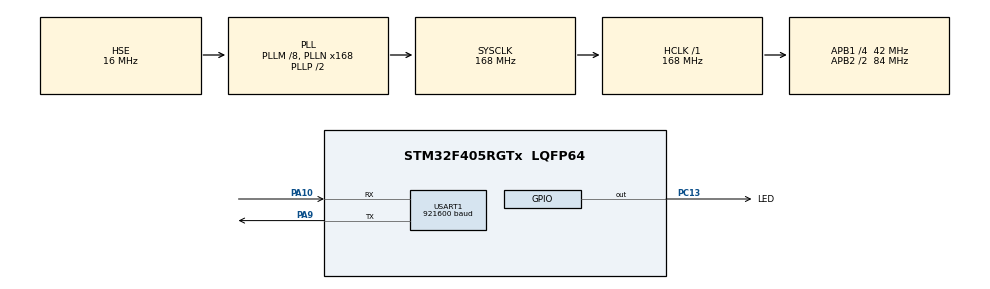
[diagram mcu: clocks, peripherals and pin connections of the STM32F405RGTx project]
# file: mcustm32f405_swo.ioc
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Mcu.Family=STM32F4
Mcu.Name=STM32F405RGTx
Mcu.Package=LQFP64
NVIC.PriorityGroup=NVIC_PRIORITYGROUP_4
NVIC.TIM2_IRQn=true\:0\:0\:false\:false\:true\:true\:true\:true
NVIC.TIM5_IRQn=true\:0\:0\:false\:false\:true\:true\:true\:true
PA10.Mode=Asynchronous
PA10.Signal=USART1_RX
PA13.Mode=Trace_Asynchronous_SW
PA13.Signal=SYS_JTMS-SWDIO
PA14.Mode=Trace_Asynchronous_SW
PA14.Signal=SYS_JTCK-SWCLK
PA9.Mode=Asynchronous
PA9.Signal=USART1_TX
PB3.Mode=Trace_Asynchronous_SW
PB3.Signal=SYS_JTDO-SWO
PC13-ANTI_TAMP.GPIO_Label=LED
PC13-ANTI_TAMP.GPIO_ModeDefaultOutputPP=GPIO_MODE_OUTPUT_OD
PC13-ANTI_TAMP.GPIO_PuPd=GPIO_NOPULL
PC13-ANTI_TAMP.PinState=GPIO_PIN_SET
PC13-ANTI_TAMP.Signal=GPIO_Output
PH0-OSC_IN.Mode=HSE-External-Oscillator
PH0-OSC_IN.Signal=RCC_OSC_IN
PH1-OSC_OUT.Mode=HSE-External-Oscillator
PH1-OSC_OUT.Signal=RCC_OSC_OUT
ProjectManager.HeapSize=0x200
ProjectManager.StackSize=0x400
ProjectManager.TargetToolchain=STM32CubeIDE
RCC.48MHZClocksFreq_Value=84000000
RCC.AHBFreq_Value=168000000
RCC.APB1CLKDivider=RCC_HCLK_DIV4
RCC.APB1Freq_Value=42000000
RCC.APB1TimFreq_Value=84000000
RCC.APB2CLKDivider=RCC_HCLK_DIV2
RCC.APB2Freq_Value=84000000
RCC.APB2TimFreq_Value=168000000
RCC.CortexFreq_Value=168000000
RCC.HCLKFreq_Value=168000000
RCC.HSE_VALUE=16000000
RCC.HSI_VALUE=16000000
RCC.LSE_VALUE=32768
RCC.PLLM=8
RCC.PLLN=168
RCC.PLLSourceVirtual=RCC_PLLSOURCE_HSE
RCC.SYSCLKFreq_VALUE=168000000
RCC.SYSCLKSource=RCC_SYSCLKSOURCE_PLLCLK
RCC.VCOOutputFreq_Value=336000000
TIM2.Period=999
TIM2.Prescaler=8399
TIM5.Period=9999
TIM5.Prescaler=8399
USART1.BaudRate=921600
USART1.VirtualMode=VM_ASYNC
VP_TIM2_VS_ClockSourceINT.Mode=Internal
VP_TIM5_VS_ClockSourceINT.Mode=Internal
board=custom

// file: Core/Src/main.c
/* USER CODE BEGIN Header */
/**
 ******************************************************************************
 * @file           : main.c
 * @brief          : Main program body
 ******************************************************************************
 * @attention
 *
 * Copyright (c) 2024 STMicroelectronics.
 * All rights reserved.
 *
 * This software is licensed under terms that can be found in the LICENSE file
 * in the root directory of this software component.
 * If no LICENSE file comes with this software, it is provided AS-IS.
 *
 ******************************************************************************
 */
/* USER CODE END Header */
#include "main.h"

TIM_HandleTypeDef htim2;
TIM_HandleTypeDef htim5;

UART_HandleTypeDef huart1;

/* USER CODE BEGIN PV */
uint32_t now = 0, last_blink = 0;
/* USER CODE END PV */

void SystemClock_Config(void);
static void MX_GPIO_Init(void);
static void MX_USART1_UART_Init(void);
static void MX_TIM2_Init(void);
static void MX_TIM5_Init(void);

/* USER CODE BEGIN 0 */

// Send stdout to USART1 and stderr to SWO
int _write(int fd, char *ptr, int len) {

    if (fd == 1) {
        HAL_StatusTypeDef hstatus;
        hstatus = HAL_UART_Transmit(&huart1, (uint8_t*) ptr, len, HAL_MAX_DELAY);
        if (hstatus == HAL_OK)
            return len;
        else
            return -1;
    } else if (fd == 2) {
        for (int i = 0; i < len; i++) {
            ITM_SendChar(ptr[i]); /* core_cm4.h */
        }
        return len;
    }
    return -1;
}

void HAL_TIM_PeriodElapsedCallback(TIM_HandleTypeDef *htim) {
    if (htim->Instance == TIM2) {
        DBG("Timer 2 interrupt fired");
    } else if (htim->Instance == TIM5) {
        DBG("Timer 5 interrupt fired");
    } else {
        DBG("Unknown timer interrupt");
    }
}

/* USER CODE END 0 */

int main(void)
{

  /* MCU Configuration--------------------------------------------------------*/

  /* Reset of all peripherals, Initializes the Flash interface and the Systick. */
  HAL_Init();

  /* Configure the system clock */
  SystemClock_Config();

  /* Initialize all configured peripherals */
  MX_GPIO_Init();
  MX_USART1_UART_Init();
  MX_TIM2_Init();
  MX_TIM5_Init();
  /* USER CODE BEGIN 2 */

    printf("Firing up demo\n");

    HAL_TIM_Base_Start_IT(&htim2);
    HAL_TIM_Base_Start_IT(&htim5);

  /* USER CODE END 2 */

  /* Infinite loop */
  /* USER CODE BEGIN WHILE */

    while (1) {

        now = HAL_GetTick();

        if (now - last_blink >= 500) {
            DBG("Blink");

            HAL_GPIO_TogglePin(LED_GPIO_Port, LED_Pin);

            last_blink = now;

        }

    /* USER CODE END WHILE */

    }
}

void SystemClock_Config(void)
{
  RCC_OscInitTypeDef RCC_OscInitStruct = {0};
  RCC_ClkInitTypeDef RCC_ClkInitStruct = {0};

  /** Configure the main internal regulator output voltage
  */
  __HAL_RCC_PWR_CLK_ENABLE();
  __HAL_PWR_VOLTAGESCALING_CONFIG(PWR_REGULATOR_VOLTAGE_SCALE1);

  /** Initializes the RCC Oscillators according to the specified parameters
  * in the RCC_OscInitTypeDef structure.
  */
  RCC_OscInitStruct.OscillatorType = RCC_OSCILLATORTYPE_HSE;
  RCC_OscInitStruct.HSEState = RCC_HSE_ON;
  RCC_OscInitStruct.PLL.PLLState = RCC_PLL_ON;
  RCC_OscInitStruct.PLL.PLLSource = RCC_PLLSOURCE_HSE;
  RCC_OscInitStruct.PLL.PLLM = 8;
  RCC_OscInitStruct.PLL.PLLN = 168;
  RCC_OscInitStruct.PLL.PLLP = RCC_PLLP_DIV2;
  RCC_OscInitStruct.PLL.PLLQ = 4;
  if (HAL_RCC_OscConfig(&RCC_OscInitStruct) != HAL_OK)
  {
    Error_Handler();
  }

  /** Initializes the CPU, AHB and APB buses clocks
  */
  RCC_ClkInitStruct.ClockType = RCC_CLOCKTYPE_HCLK|RCC_CLOCKTYPE_SYSCLK
                              |RCC_CLOCKTYPE_PCLK1|RCC_CLOCKTYPE_PCLK2;
  RCC_ClkInitStruct.SYSCLKSource = RCC_SYSCLKSOURCE_PLLCLK;
  RCC_ClkInitStruct.AHBCLKDivider = RCC_SYSCLK_DIV1;
  RCC_ClkInitStruct.APB1CLKDivider = RCC_HCLK_DIV4;
  RCC_ClkInitStruct.APB2CLKDivider = RCC_HCLK_DIV2;

  if (HAL_RCC_ClockConfig(&RCC_ClkInitStruct, FLASH_LATENCY_5) != HAL_OK)
  {
    Error_Handler();
  }
}

static void MX_TIM2_Init(void)
{

  TIM_ClockConfigTypeDef sClockSourceConfig = {0};
  TIM_MasterConfigTypeDef sMasterConfig = {0};

  htim2.Instance = TIM2;
  htim2.Init.Prescaler = 8399;
  htim2.Init.CounterMode = TIM_COUNTERMODE_UP;
  htim2.Init.Period = 999;
  htim2.Init.ClockDivision = TIM_CLOCKDIVISION_DIV1;
  htim2.Init.AutoReloadPreload = TIM_AUTORELOAD_PRELOAD_DISABLE;
  if (HAL_TIM_Base_Init(&htim2) != HAL_OK)
  {
    Error_Handler();
  }
  sClockSourceConfig.ClockSource = TIM_CLOCKSOURCE_INTERNAL;
  if (HAL_TIM_ConfigClockSource(&htim2, &sClockSourceConfig) != HAL_OK)
  {
    Error_Handler();
  }
  sMasterConfig.MasterOutputTrigger = TIM_TRGO_RESET;
  sMasterConfig.MasterSlaveMode = TIM_MASTERSLAVEMODE_DISABLE;
  if (HAL_TIMEx_MasterConfigSynchronization(&htim2, &sMasterConfig) != HAL_OK)
  {
    Error_Handler();
  }

}

static void MX_TIM5_Init(void)
{

  TIM_ClockConfigTypeDef sClockSourceConfig = {0};
  TIM_MasterConfigTypeDef sMasterConfig = {0};

  htim5.Instance = TIM5;
  htim5.Init.Prescaler = 8399;
  htim5.Init.CounterMode = TIM_COUNTERMODE_UP;
  htim5.Init.Period = 9999;
  htim5.Init.ClockDivision = TIM_CLOCKDIVISION_DIV1;
  htim5.Init.AutoReloadPreload = TIM_AUTORELOAD_PRELOAD_DISABLE;
  if (HAL_TIM_Base_Init(&htim5) != HAL_OK)
  {
    Error_Handler();
  }
  sClockSourceConfig.ClockSource = TIM_CLOCKSOURCE_INTERNAL;
  if (HAL_TIM_ConfigClockSource(&htim5, &sClockSourceConfig) != HAL_OK)
  {
    Error_Handler();
  }
  sMasterConfig.MasterOutputTrigger = TIM_TRGO_RESET;
  sMasterConfig.MasterSlaveMode = TIM_MASTERSLAVEMODE_DISABLE;
  if (HAL_TIMEx_MasterConfigSynchronization(&htim5, &sMasterConfig) != HAL_OK)
  {
    Error_Handler();
  }

}

static void MX_USART1_UART_Init(void)
{

  huart1.Instance = USART1;
  huart1.Init.BaudRate = 921600;
  huart1.Init.WordLength = UART_WORDLENGTH_8B;
  huart1.Init.StopBits = UART_STOPBITS_1;
  huart1.Init.Parity = UART_PARITY_NONE;
  huart1.Init.Mode = UART_MODE_TX_RX;
  huart1.Init.HwFlowCtl = UART_HWCONTROL_NONE;
  huart1.Init.OverSampling = UART_OVERSAMPLING_16;
  if (HAL_UART_Init(&huart1) != HAL_OK)
  {
    Error_Handler();
  }

}

static void MX_GPIO_Init(void)
{
  GPIO_InitTypeDef GPIO_InitStruct = {0};

  /* GPIO Ports Clock Enable */
  __HAL_RCC_GPIOC_CLK_ENABLE();
  __HAL_RCC_GPIOH_CLK_ENABLE();
  __HAL_RCC_GPIOA_CLK_ENABLE();
  __HAL_RCC_GPIOB_CLK_ENABLE();

  /*Configure GPIO pin Output Level */
  HAL_GPIO_WritePin(LED_GPIO_Port, LED_Pin, GPIO_PIN_SET);

  /*Configure GPIO pin : LED_Pin */
  GPIO_InitStruct.Pin = LED_Pin;
  GPIO_InitStruct.Mode = GPIO_MODE_OUTPUT_OD;
  GPIO_InitStruct.Pull = GPIO_NOPULL;
  GPIO_InitStruct.Speed = GPIO_SPEED_FREQ_LOW;
  HAL_GPIO_Init(LED_GPIO_Port, &GPIO_InitStruct);

}

void Error_Handler(void)
{
    __disable_irq();
    while (1)
    {
    }
}
